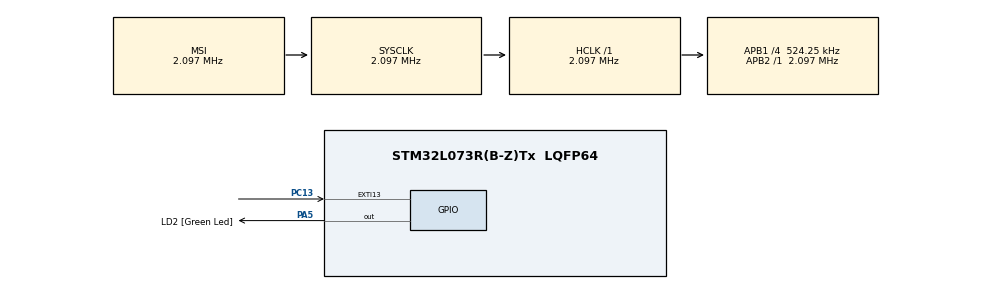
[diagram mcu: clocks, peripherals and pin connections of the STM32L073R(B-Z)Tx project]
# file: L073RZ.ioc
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Mcu.Family=STM32L0
RCC.MSI_VALUE=2097000
PC15-OSC32_OUT.Mode=LSE-External-Oscillator
PH0-OSC_IN.Signal=RCC_OSC_IN
PC13.Signal=GPXTI13
PA14.GPIO_Label=TCK
RCC.APB1CLKDivider=RCC_HCLK_DIV4
PC14-OSC32_IN.Signal=RCC_OSC32_IN
ProjectManager.StackSize=0x400
PA13.Signal=SYS_SWDIO
RCC.HSI16_VALUE=16000000
NVIC.RCC_CRS_IRQn=true\:0\:0\:false\:false\:true\:true\:false
ProjectManager.TargetToolchain=STM32CubeIDE
RCC.HCLKFreq_Value=2097000
RCC.APB2TimFreq_Value=2097000
PC15-OSC32_OUT.Signal=RCC_OSC32_OUT
RCC.AHBFreq_Value=2097000
PH0-OSC_IN.Mode=HSE-External-Clock-Source
PH0-OSC_IN.GPIO_Label=MCO
PA5.Signal=GPIO_Output
RCC.HSE_VALUE=8000000
board=NUCLEO-L073RZ
RCC.VCOOutputFreq_Value=48000000
RCC.APB2Freq_Value=2097000
PC14-OSC32_IN.Mode=LSE-External-Oscillator
VP_TIM2_VS_ClockSourceINT.Mode=Internal
PA14.Mode=Serial_Wire
PA13.Mode=Serial_Wire
Mcu.Name=STM32L073R(B-Z)Tx
PA13.GPIO_Label=TMS
RCC.SYSCLKFreq_VALUE=2097000
Mcu.Package=LQFP64
PA5.GPIO_Label=LD2 [Green Led]
PA14.Signal=SYS_SWCLK
ProjectManager.HeapSize=0x200
RCC.HSI_VALUE=16000000
RCC.APB1TimFreq_Value=1048500
RCC.APB1Freq_Value=524250
NVIC.EXTI4_15_IRQn=true\:0\:0\:false\:false\:true\:true\:true
RCC.HSI48_VALUE=48000000

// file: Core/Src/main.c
/* USER CODE BEGIN Header */
/**
  ******************************************************************************
  * @file           : main.c
  * @brief          : Main program body
  ******************************************************************************
  * @attention
  *
  * <h2><center>&copy; Copyright (c) 2021 STMicroelectronics.
  * All rights reserved.</center></h2>
  *
  * This software component is licensed by ST under BSD 3-Clause license,
  * the "License"; You may not use this file except in compliance with the
  * License. You may obtain a copy of the License at:
  *                        opensource.org/licenses/BSD-3-Clause
  *
  ******************************************************************************
  */
/* USER CODE END Header */
#include "main.h"
#include "stm32l0.h"

TIM_HandleTypeDef htim2;

void SystemClock_Config(void);
static void MX_GPIO_Init(void);
static void MX_TIM2_Init(void);
/* USER CODE BEGIN PFP */
int32_t Counter=1;
/* USER CODE END PFP */

/* USER CODE BEGIN 0 */

extern void Delay(uint16_t delay)
{
__HAL_TIM_SET_COUNTER(&htim2,0);
while(__HAL_TIM_GET_COUNTER(&htim2) < delay);
}
/* USER CODE END 0 */

int main(void)
{

  /* MCU Configuration--------------------------------------------------------*/

  /* Reset of all peripherals, Initializes the Flash interface and the Systick. */
  HAL_Init();

  /* Configure the system clock */
  SystemClock_Config();

  /* Initialize all configured peripherals */
  MX_GPIO_Init();
  MX_TIM2_Init();
  /* USER CODE BEGIN 2 */
  GPIO_InitTypeDef GPIO_InitStruct; /* GPIO Ports Clock Enable */
      __GPIOB_CLK_ENABLE();
      GPIO_InitStruct.Pin = GPIO_PIN_0;
      GPIO_InitStruct.Mode = GPIO_MODE_OUTPUT_PP;     // digital Output
      GPIO_InitStruct.Speed = GPIO_SPEED_HIGH;
      HAL_GPIO_Init(GPIOB, &GPIO_InitStruct);

      GPIO_InitStruct.Pin = GPIO_PIN_10;
      GPIO_InitStruct.Mode = GPIO_MODE_INPUT;     // digital input
      GPIO_InitStruct.Speed = GPIO_SPEED_HIGH;
      HAL_GPIO_Init(GPIOB, &GPIO_InitStruct);
  /* USER CODE END 2 */
      HAL_TIM_Base_Start(&htim2);
      STM32L0_main();
  /* Infinite loop */
  while (1)
  {

  }
}

void SystemClock_Config(void)
{
  RCC_OscInitTypeDef RCC_OscInitStruct = {0};
  RCC_ClkInitTypeDef RCC_ClkInitStruct = {0};

  /** Configure the main internal regulator output voltage
  */
  __HAL_PWR_VOLTAGESCALING_CONFIG(PWR_REGULATOR_VOLTAGE_SCALE1);
  /** Initializes the RCC Oscillators according to the specified parameters
  * in the RCC_OscInitTypeDef structure.
  */
  RCC_OscInitStruct.OscillatorType = RCC_OSCILLATORTYPE_MSI;
  RCC_OscInitStruct.MSIState = RCC_MSI_ON;
  RCC_OscInitStruct.MSICalibrationValue = 0;
  RCC_OscInitStruct.MSIClockRange = RCC_MSIRANGE_5;
  RCC_OscInitStruct.PLL.PLLState = RCC_PLL_NONE;
  if (HAL_RCC_OscConfig(&RCC_OscInitStruct) != HAL_OK)
  {
    Error_Handler();
  }
  /** Initializes the CPU, AHB and APB buses clocks
  */
  RCC_ClkInitStruct.ClockType = RCC_CLOCKTYPE_HCLK|RCC_CLOCKTYPE_SYSCLK
                              |RCC_CLOCKTYPE_PCLK1|RCC_CLOCKTYPE_PCLK2;
  RCC_ClkInitStruct.SYSCLKSource = RCC_SYSCLKSOURCE_MSI;
  RCC_ClkInitStruct.AHBCLKDivider = RCC_SYSCLK_DIV1;
  RCC_ClkInitStruct.APB1CLKDivider = RCC_HCLK_DIV4;
  RCC_ClkInitStruct.APB2CLKDivider = RCC_HCLK_DIV1;

  if (HAL_RCC_ClockConfig(&RCC_ClkInitStruct, FLASH_LATENCY_0) != HAL_OK)
  {
    Error_Handler();
  }
}

static void MX_TIM2_Init(void)
{

  TIM_ClockConfigTypeDef sClockSourceConfig = {0};
  TIM_MasterConfigTypeDef sMasterConfig = {0};

  htim2.Instance = TIM2;
  htim2.Init.Prescaler = 0;
  htim2.Init.CounterMode = TIM_COUNTERMODE_UP;
  htim2.Init.Period = 65535;
  htim2.Init.ClockDivision = TIM_CLOCKDIVISION_DIV1;
  htim2.Init.AutoReloadPreload = TIM_AUTORELOAD_PRELOAD_DISABLE;
  if (HAL_TIM_Base_Init(&htim2) != HAL_OK)
  {
    Error_Handler();
  }
  sClockSourceConfig.ClockSource = TIM_CLOCKSOURCE_INTERNAL;
  if (HAL_TIM_ConfigClockSource(&htim2, &sClockSourceConfig) != HAL_OK)
  {
    Error_Handler();
  }
  sMasterConfig.MasterOutputTrigger = TIM_TRGO_RESET;
  sMasterConfig.MasterSlaveMode = TIM_MASTERSLAVEMODE_DISABLE;
  if (HAL_TIMEx_MasterConfigSynchronization(&htim2, &sMasterConfig) != HAL_OK)
  {
    Error_Handler();
  }

}

static void MX_GPIO_Init(void)
{
  GPIO_InitTypeDef GPIO_InitStruct = {0};

  /* GPIO Ports Clock Enable */
  __HAL_RCC_GPIOC_CLK_ENABLE();
  __HAL_RCC_GPIOH_CLK_ENABLE();
  __HAL_RCC_GPIOA_CLK_ENABLE();

  /*Configure GPIO pin Output Level */
  HAL_GPIO_WritePin(LD2_GPIO_Port, LD2_Pin, GPIO_PIN_RESET);

  /*Configure GPIO pin : PC13 */
  GPIO_InitStruct.Pin = GPIO_PIN_13;
  GPIO_InitStruct.Mode = GPIO_MODE_IT_RISING;
  GPIO_InitStruct.Pull = GPIO_NOPULL;
  HAL_GPIO_Init(GPIOC, &GPIO_InitStruct);

  /*Configure GPIO pin : LD2_Pin */
  GPIO_InitStruct.Pin = LD2_Pin;
  GPIO_InitStruct.Mode = GPIO_MODE_OUTPUT_PP;
  GPIO_InitStruct.Pull = GPIO_NOPULL;
  GPIO_InitStruct.Speed = GPIO_SPEED_FREQ_LOW;
  HAL_GPIO_Init(LD2_GPIO_Port, &GPIO_InitStruct);

  /* EXTI interrupt init*/
  HAL_NVIC_SetPriority(EXTI4_15_IRQn, 0, 0);
  HAL_NVIC_EnableIRQ(EXTI4_15_IRQn);

}

void Error_Handler(void)
{
  __disable_irq();
  while (1)
  {
  }
}

/************************ (C) COPYRIGHT STMicroelectronics *****END OF FILE****/
